AUTOSAR XML (schema 4-3-0)
package /BMW/Platform/Omc/SwcImplementations
  swc implementation Omc_Implementation: behavior=InternalBehavior
    code-descriptors:
      code Default: artifact-descriptors=autosar-engineering-object={short-label=Default, category=SWSRC}
package /BMW/Platform/Omc/SwComponentTypes
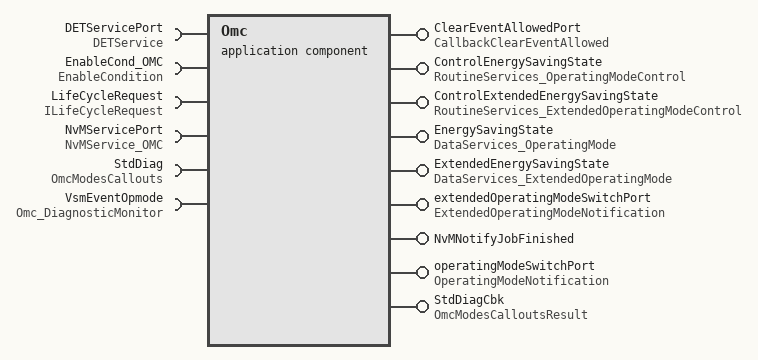
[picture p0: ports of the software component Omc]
  application sw component type Omc
    9 x provide port:
      ClearEventAllowedPort: server-com-spec{operation=ClearEventAllowed, queue-length=1}, provided-interface=CallbackClearEventAllowed
      ControlEnergySavingState: server-com-spec{operation=Start, queue-length=1}, provided-interface=RoutineServices_OperatingModeControl
      ControlExtendedEnergySavingState: server-com-spec{operation=Start, queue-length=1}, provided-interface=RoutineServices_ExtendedOperatingModeControl
      EnergySavingState: provided-com-specs=[{operation=ConditionCheckRead, queue-length=1}, {operation=ReadData, queue-length=1}], provided-interface=DataServices_OperatingMode
      ExtendedEnergySavingState: provided-com-specs=[{operation=ConditionCheckRead, queue-length=1}, {operation=ReadData, queue-length=1}], provided-interface=DataServices_ExtendedOperatingMode
      extendedOperatingModeSwitchPort: mode-switch-sender-com-spec{enhanced-mode-api=false, mode-group=currentExtendedOperatingMode, queue-length=1}, provided-interface=ExtendedOperatingModeNotification
      NvMNotifyJobFinished: server-com-spec{operation=JobFinished, queue-length=1}, provided-interface=NvMNotifyJobFinished
      operatingModeSwitchPort: mode-switch-sender-com-spec{enhanced-mode-api=false, mode-group=currentOperatingMode, queue-length=1}, provided-interface=OperatingModeNotification
      StdDiagCbk: provided-interface=OmcModesCalloutsResult
        provided-com-specs:
          operation=OpModeSwitchAllowedResult, queue-length=1
          operation=OpModeSwitchCancelledAck, queue-length=1
    provide/require port LifeCycle: mode-switch-sender-com-spec{enhanced-mode-api=true, mode-group=Mode, queue-length=2}, mode-switch-receiver-com-spec{enhanced-mode-api=true, supports-asynchronous-mode-switch=false}, provided-required-interface=ILifeCycle
    6 x require port:
      DETServicePort: required-interface=DETService
      EnableCond_OMC: required-interface=EnableCondition
      LifeCycleRequest: nonqueued-receiver-com-spec{data-element=requestMode, filter=data-filter-type=ALWAYS, init-value=2}, required-interface=ILifeCycleRequest
      NvMServicePort: required-interface=NvMService_OMC
      StdDiag: required-interface=OmcModesCallouts
      VsmEventOpmode: required-interface=Omc_DiagnosticMonitor
    behavior InternalBehavior: data-type-mapping=Omc_DataTypeMappingSets, included-data-type-set=data-type=[Omc_ExtendedOperatingModeType, Omc_OperatingModeType]
      exclusive area Mode
      5 x operation invoked event:
        E_ChangeExtendedOperatingMode: start-on-event=ChangeExtendedOperatingMode, operation=ControlExtendedEnergySavingState.Start
        E_ChangeOperatingMode: start-on-event=ChangeOperatingMode, operation=ControlEnergySavingState.Start
        E_ClearEventAllowed: start-on-event=ClearEventAllowed, operation=ClearEventAllowedPort.ClearEventAllowed
        E_ConditionCheckReadExtendedOperatingMode: start-on-event=ConditionCheckReadExtendedOperatingMode, operation=ExtendedEnergySavingState.ConditionCheckRead
        E_ConditionCheckReadDIDOperatingMode: start-on-event=ConditionCheckReadOperatingMode, operation=EnergySavingState.ConditionCheckRead
      data received event LifeCycleRequest: start-on-event=LifeCycleHandler, data=LifeCycleRequest.requestMode
      5 x operation invoked event:
        E_NvMNotifyJobFinished: start-on-event=NvMWriteJobFinished, operation=NvMNotifyJobFinished.JobFinished
        E_ReadDIDExtendedOperatingMode: start-on-event=ReadDIDExtendedOperatingMode, operation=ExtendedEnergySavingState.ReadData
        E_ReadOperatingMode: start-on-event=ReadOperatingMode, operation=EnergySavingState.ReadData
        E_StdDiag_OpModeSwitchAllowedResult: start-on-event=StdDiag_OpModeSwitchAllowedResult, operation=StdDiagCbk.OpModeSwitchAllowedResult
        E_StdDiag_OpModeSwitchCancelledAck: start-on-event=StdDiag_OpModeSwitchCancelledAck, operation=StdDiagCbk.OpModeSwitchCancelledAck
      11 x runnable:
        ChangeExtendedOperatingMode: can-enter-exclusive-area=Mode, can-be-invoked-concurrently=true, symbol=Omc_RoutineControlStartExtendedOperatingMode
          5 x sync call, all with timeout=0:
            SSCP_GetErrorStatus: operation=NvMServicePort.GetErrorStatus
            SSCP_OmcStdDiagOpModeCallout: operation=StdDiag.AllowOpModeSwitch
            SSCP_OmcStdDiagOpModeCancelledCallout: operation=StdDiag.OpModeSwitchCancelled
            SSCP_ReportError: operation=DETServicePort.ReportError
            SSCP_WriteBlock: operation=NvMServicePort.WriteBlock
        ChangeOperatingMode: can-enter-exclusive-area=Mode, can-be-invoked-concurrently=true, symbol=Omc_RoutineControlStartOperatingMode
          5 x sync call, all with timeout=0:
            SSCP_GetErrorStatus: operation=NvMServicePort.GetErrorStatus
            SSCP_OmcStdDiagOpModeCallout: operation=StdDiag.AllowOpModeSwitch
            SSCP_OmcStdDiagOpModeCancelledCallout: operation=StdDiag.OpModeSwitchCancelled
            SSCP_ReportError: operation=DETServicePort.ReportError
            SSCP_WriteBlock: operation=NvMServicePort.WriteBlock
        ClearEventAllowed: can-enter-exclusive-area=Mode, can-be-invoked-concurrently=true, symbol=Omc_ClearEventAllowed
          sync call SSCP_ReportError: operation=DETServicePort.ReportError, timeout=0
        ConditionCheckReadExtendedOperatingMode: can-enter-exclusive-area=Mode, can-be-invoked-concurrently=true, symbol=Omc_ConditionCheckReadDIDExtendedOperatingMode
          sync call SSCP_ReportError: operation=DETServicePort.ReportError, timeout=0
        ConditionCheckReadOperatingMode: can-enter-exclusive-area=Mode, can-be-invoked-concurrently=true, symbol=Omc_ConditionCheckReadDIDOperatingMode
          sync call SSCP_ReportError: operation=DETServicePort.ReportError, timeout=0
        LifeCycleHandler: can-enter-exclusive-area=Mode, mode-access-point=LifeCycle.Mode, symbol=Omc_LifeCycleHandler
          data-read-access:
            access requestedMode: accessed-variable=LifeCycleRequest.requestMode
          mode switch point LifeCycle: mode-group=LifeCycle.Mode
          mode switch point MSP_currentExtendedOperatingMode: mode-group=extendedOperatingModeSwitchPort.currentExtendedOperatingMode
          mode switch point MSP_currentOperatingMode: mode-group=operatingModeSwitchPort.currentOperatingMode
          sync call SSCP_ReportError: operation=DETServicePort.ReportError, timeout=0
          sync call SSCP_SetEnableCondition: operation=EnableCond_OMC.SetEnableCondition, timeout=0
          sync call SSCP_SetEventStatus: operation=VsmEventOpmode.SetEventStatus, timeout=0
        NvMWriteJobFinished: can-enter-exclusive-area=Mode, can-be-invoked-concurrently=true, symbol=Omc_NvMNotifyJobFinishedOperatingModes
          mode switch point MSP_currentExtendedOperatingMode: mode-group=extendedOperatingModeSwitchPort.currentExtendedOperatingMode
          mode switch point MSP_currentOperatingMode: mode-group=operatingModeSwitchPort.currentOperatingMode
          5 x sync call, all with timeout=0:
            SSCP_GetErrorStatus: operation=NvMServicePort.GetErrorStatus
            SSCP_ReportError: operation=DETServicePort.ReportError
            SSCP_SetEnableCondition: operation=EnableCond_OMC.SetEnableCondition
            SSCP_SetEventStatus: operation=VsmEventOpmode.SetEventStatus
            SSCP_WriteBlock: operation=NvMServicePort.WriteBlock
        ReadDIDExtendedOperatingMode: can-enter-exclusive-area=Mode, can-be-invoked-concurrently=true, symbol=Omc_ReadDIDExtendedOperatingMode
          sync call SSCP_ReportError: operation=DETServicePort.ReportError, timeout=0
        ReadOperatingMode: can-enter-exclusive-area=Mode, can-be-invoked-concurrently=true, symbol=Omc_ReadDIDOperatingMode
          sync call SSCP_ReportError: operation=DETServicePort.ReportError, timeout=0
        StdDiag_OpModeSwitchAllowedResult: can-be-invoked-concurrently=true, symbol=Omc_StdDiag_OpModeSwitchAllowedResult
        StdDiag_OpModeSwitchCancelledAck: can-be-invoked-concurrently=true, symbol=Omc_StdDiag_OpModeSwitchCancelledAck
      swc service dependency OmcDependencyNVMData: assigned-ports=role-based-port-assignment={port-prototype=NvMServicePort, role=NvmService}
        service-needs:
          nv block needs OmcNvBlockNeeds_Data: calc-ram-block-crc=false, n-data-sets=1, n-rom-blocks=1, restore-at-start=true, store-at-shutdown=false
